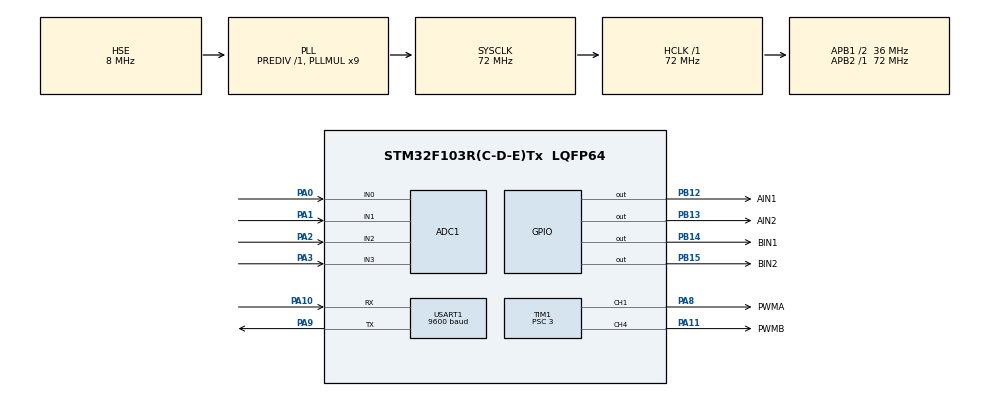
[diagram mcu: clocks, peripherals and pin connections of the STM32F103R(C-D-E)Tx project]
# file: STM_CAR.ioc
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ADC1.Channel-0\#ChannelRegularConversion=ADC_CHANNEL_0
ADC1.Channel-1\#ChannelRegularConversion=ADC_CHANNEL_1
ADC1.Channel-2\#ChannelRegularConversion=ADC_CHANNEL_2
ADC1.Channel-3\#ChannelRegularConversion=ADC_CHANNEL_3
ADC1.NbrOfConversion=4
ADC1.NbrOfConversionFlag=1
ADC1.Rank-0\#ChannelRegularConversion=1
ADC1.Rank-1\#ChannelRegularConversion=2
ADC1.Rank-2\#ChannelRegularConversion=3
ADC1.Rank-3\#ChannelRegularConversion=4
ADC1.SamplingTime-0\#ChannelRegularConversion=ADC_SAMPLETIME_55CYCLES_5
ADC1.SamplingTime-1\#ChannelRegularConversion=ADC_SAMPLETIME_55CYCLES_5
ADC1.SamplingTime-2\#ChannelRegularConversion=ADC_SAMPLETIME_55CYCLES_5
ADC1.SamplingTime-3\#ChannelRegularConversion=ADC_SAMPLETIME_55CYCLES_5
ADC1.master=1
Dma.ADC1.0.Direction=DMA_PERIPH_TO_MEMORY
Dma.ADC1.0.Instance=DMA1_Channel1
Dma.ADC1.0.MemDataAlignment=DMA_MDATAALIGN_HALFWORD
Dma.ADC1.0.MemInc=DMA_MINC_ENABLE
Dma.ADC1.0.Mode=DMA_CIRCULAR
Dma.ADC1.0.PeriphDataAlignment=DMA_PDATAALIGN_HALFWORD
Dma.ADC1.0.PeriphInc=DMA_PINC_DISABLE
Dma.ADC1.0.Priority=DMA_PRIORITY_HIGH
Dma.Request0=ADC1
Mcu.Family=STM32F1
Mcu.Name=STM32F103R(C-D-E)Tx
Mcu.Package=LQFP64
NVIC.DMA1_Channel1_IRQn=true\:0\:0\:false\:false\:true\:false\:true\:true
NVIC.PriorityGroup=NVIC_PRIORITYGROUP_4
NVIC.USART1_IRQn=true\:0\:0\:false\:false\:true\:true\:true\:true
PA0-WKUP.GPIO_Mode=GPIO_MODE_ANALOG
PA0-WKUP.Signal=ADCx_IN0
PA1.GPIO_Mode=GPIO_MODE_ANALOG
PA1.Signal=ADCx_IN1
PA10.GPIO_PuPd=GPIO_NOPULL
PA10.Mode=Asynchronous
PA10.Signal=USART1_RX
PA11.GPIO_Label=PWMB
PA11.GPIO_Speed=GPIO_SPEED_FREQ_HIGH
PA11.Signal=S_TIM1_CH4
PA13.Mode=Serial_Wire
PA13.Signal=SYS_JTMS-SWDIO
PA14.Mode=Serial_Wire
PA14.Signal=SYS_JTCK-SWCLK
PA2.GPIO_Mode=GPIO_MODE_ANALOG
PA2.Signal=ADCx_IN2
PA3.GPIO_Mode=GPIO_MODE_ANALOG
PA3.Signal=ADCx_IN3
PA8.GPIO_Label=PWMA
PA8.GPIO_Speed=GPIO_SPEED_FREQ_LOW
PA8.Signal=S_TIM1_CH1
PA9.GPIO_Speed=GPIO_SPEED_FREQ_HIGH
PA9.Mode=Asynchronous
PA9.Signal=USART1_TX
PB12.GPIO_Label=AIN1
PB12.GPIO_Speed=GPIO_SPEED_FREQ_LOW
PB12.Signal=GPIO_Output
PB13.GPIO_Label=AIN2
PB13.GPIO_Speed=GPIO_SPEED_FREQ_LOW
PB13.Signal=GPIO_Output
PB14.GPIO_Label=BIN1
PB14.GPIO_Speed=GPIO_SPEED_FREQ_LOW
PB14.Signal=GPIO_Output
PB15.GPIO_Label=BIN2
PB15.GPIO_Speed=GPIO_SPEED_FREQ_LOW
PB15.Signal=GPIO_Output
PD0-OSC_IN.Mode=HSE-External-Oscillator
PD0-OSC_IN.Signal=RCC_OSC_IN
PD1-OSC_OUT.Mode=HSE-External-Oscillator
PD1-OSC_OUT.Signal=RCC_OSC_OUT
ProjectManager.HeapSize=0x200
ProjectManager.StackSize=0x400
ProjectManager.TargetToolchain=MDK-ARM V5.32
RCC.ADCPresc=RCC_ADCPCLK2_DIV6
RCC.AHBFreq_Value=72000000
RCC.APB1CLKDivider=RCC_HCLK_DIV2
RCC.APB1Freq_Value=36000000
RCC.APB1TimFreq_Value=72000000
RCC.APB2Freq_Value=72000000
RCC.APB2TimFreq_Value=72000000
RCC.HCLKFreq_Value=72000000
RCC.PLLMUL=RCC_PLL_MUL9
RCC.PLLSourceVirtual=RCC_PLLSOURCE_HSE
RCC.SYSCLKFreq_VALUE=72000000
RCC.SYSCLKSource=RCC_SYSCLKSOURCE_PLLCLK
RCC.USBFreq_Value=72000000
SH.ADCx_IN0.0=ADC1_IN0,IN0
SH.ADCx_IN1.0=ADC1_IN1,IN1
SH.ADCx_IN2.0=ADC1_IN2,IN2
SH.ADCx_IN3.0=ADC1_IN3,IN3
SH.S_TIM1_CH1.0=TIM1_CH1,PWM Generation1 CH1
SH.S_TIM1_CH4.0=TIM1_CH4,PWM Generation4 CH4
TIM1.Channel-PWM\ Generation1\ CH1=TIM_CHANNEL_1
TIM1.Channel-PWM\ Generation4\ CH4=TIM_CHANNEL_4
TIM1.Period=999
TIM1.Prescaler=3
USART1.BaudRate=9600
USART1.VirtualMode=VM_ASYNC
board=custom

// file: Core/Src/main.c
/* USER CODE BEGIN Header */
/**
  ******************************************************************************
  * @file           : main.c
  * @brief          : Main program body
  ******************************************************************************
  * @attention
  *
  * Copyright (c) 2023 STMicroelectronics.
  * All rights reserved.
  *
  * This software is licensed under terms that can be found in the LICENSE file
  * in the root directory of this software component.
  * If no LICENSE file comes with this software, it is provided AS-IS.
  *
  ******************************************************************************
  */
/* USER CODE END Header */
#include "main.h"
#include "adc.h"
#include "dma.h"
#include "tim.h"
#include "usart.h"
#include "gpio.h"

/* USER CODE BEGIN Includes */
#include "motor.h"
#include "stdio.h"
/* USER CODE END Includes */

/* USER CODE BEGIN PTD */
uint16_t ADCDate[4];
/* USER CODE END PTD */

void SystemClock_Config(void);

/* USER CODE BEGIN 0 */

#ifdef __GNUC__
#define PUTCHAR_PROTOTYPE int __io_putchar(int ch)
#else
#define PUTCHAR_PROTOTYPE int fputc(int ch, FILE *f)
#endif
PUTCHAR_PROTOTYPE
{
    HAL_UART_Transmit(&huart1 , (uint8_t *)&ch, 1, 0xFFFF);
    return ch;
}

/* USER CODE END 0 */

int main(void)
{

  /* MCU Configuration--------------------------------------------------------*/

  /* Reset of all peripherals, Initializes the Flash interface and the Systick. */
  HAL_Init();

  /* Configure the system clock */
  SystemClock_Config();

  /* Initialize all configured peripherals */
  MX_GPIO_Init();
  MX_DMA_Init();
  MX_TIM1_Init();
  MX_ADC1_Init();
  MX_USART1_UART_Init();
  /* USER CODE BEGIN 2 */

     HAL_TIM_PWM_Start(&htim1, TIM_CHANNEL_1);
     HAL_TIM_PWM_Start(&htim1, TIM_CHANNEL_4);
  /* USER CODE END 2 */

  /* Infinite loop */
  while (1)
  {
//     HAL_ADC_Start_DMA(&hadc1,(uint32_t*)ADCDate,sizeof(ADCDate)/sizeof(ADCDate[0]));
//     printf("%d %d %d %d\n\r",ADCDate[0],ADCDate[1],ADCDate[2],ADCDate[3]);
//     HAL_Delay(1000);
     MotorControl(2, 900, 900); //直行
  }
}

void SystemClock_Config(void)
{
  RCC_OscInitTypeDef RCC_OscInitStruct = {0};
  RCC_ClkInitTypeDef RCC_ClkInitStruct = {0};
  RCC_PeriphCLKInitTypeDef PeriphClkInit = {0};

  /** Initializes the RCC Oscillators according to the specified parameters
  * in the RCC_OscInitTypeDef structure.
  */
  RCC_OscInitStruct.OscillatorType = RCC_OSCILLATORTYPE_HSE;
  RCC_OscInitStruct.HSEState = RCC_HSE_ON;
  RCC_OscInitStruct.HSEPredivValue = RCC_HSE_PREDIV_DIV1;
  RCC_OscInitStruct.HSIState = RCC_HSI_ON;
  RCC_OscInitStruct.PLL.PLLState = RCC_PLL_ON;
  RCC_OscInitStruct.PLL.PLLSource = RCC_PLLSOURCE_HSE;
  RCC_OscInitStruct.PLL.PLLMUL = RCC_PLL_MUL9;
  if (HAL_RCC_OscConfig(&RCC_OscInitStruct) != HAL_OK)
  {
    Error_Handler();
  }

  /** Initializes the CPU, AHB and APB buses clocks
  */
  RCC_ClkInitStruct.ClockType = RCC_CLOCKTYPE_HCLK|RCC_CLOCKTYPE_SYSCLK
                              |RCC_CLOCKTYPE_PCLK1|RCC_CLOCKTYPE_PCLK2;
  RCC_ClkInitStruct.SYSCLKSource = RCC_SYSCLKSOURCE_PLLCLK;
  RCC_ClkInitStruct.AHBCLKDivider = RCC_SYSCLK_DIV1;
  RCC_ClkInitStruct.APB1CLKDivider = RCC_HCLK_DIV2;
  RCC_ClkInitStruct.APB2CLKDivider = RCC_HCLK_DIV1;

  if (HAL_RCC_ClockConfig(&RCC_ClkInitStruct, FLASH_LATENCY_2) != HAL_OK)
  {
    Error_Handler();
  }
  PeriphClkInit.PeriphClockSelection = RCC_PERIPHCLK_ADC;
  PeriphClkInit.AdcClockSelection = RCC_ADCPCLK2_DIV6;
  if (HAL_RCCEx_PeriphCLKConfig(&PeriphClkInit) != HAL_OK)
  {
    Error_Handler();
  }
}

void Error_Handler(void)
{
  __disable_irq();
  while (1)
  {
  }
}
